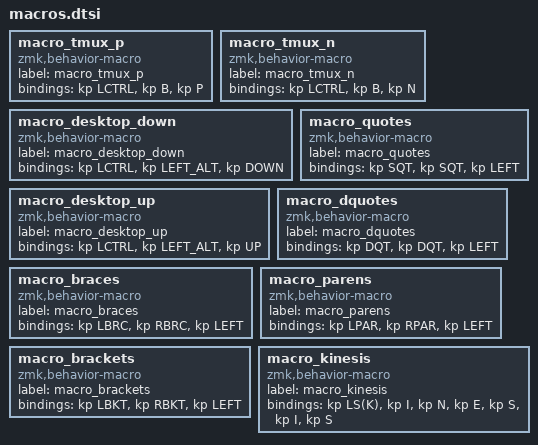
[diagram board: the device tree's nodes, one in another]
macro_tmux_p: macro_tmux_p{
compatible = "zmk,behavior-macro";
label = "macro_tmux_p";
#binding-cells = <0>;
bindings = <&kp LCTRL>, <&kp B>, <&kp P>;
};
macro_tmux_n: macro_tmux_n{
compatible = "zmk,behavior-macro";
label = "macro_tmux_n";
#binding-cells = <0>;
bindings = <&kp LCTRL>, <&kp B>, <&kp N>;
};
macro_desktop_down: macro_desktop_down{
compatible = "zmk,behavior-macro";
label = "macro_desktop_down";
#binding-cells = <0>;
bindings = <&kp LCTRL>, <&kp LEFT_ALT>, <&kp DOWN>;
};
macro_desktop_up: macro_desktop_up{
compatible = "zmk,behavior-macro";
label = "macro_desktop_up";
#binding-cells = <0>;
bindings = <&kp LCTRL>, <&kp LEFT_ALT>, <&kp UP>;
};
macro_quotes: macro_quotes{
compatible = "zmk,behavior-macro";
label = "macro_quotes";
#binding-cells = <0>;
bindings = <&kp SQT>, <&kp SQT>, <&kp LEFT>;
};
macro_dquotes: macro_dquotes{
compatible = "zmk,behavior-macro";
label = "macro_dquotes";
#binding-cells = <0>;
bindings = <&kp DQT>, <&kp DQT>, <&kp LEFT>;
};
macro_braces: macro_braces{
compatible = "zmk,behavior-macro";
label = "macro_braces";
#binding-cells = <0>;
bindings = <&kp LBRC>, <&kp RBRC>, <&kp LEFT>;
};
macro_parens: macro_parens{
compatible = "zmk,behavior-macro";
label = "macro_parens";
#binding-cells = <0>;
bindings = <&kp LPAR>, <&kp RPAR>, <&kp LEFT>;
};
macro_brackets: macro_brackets{
compatible = "zmk,behavior-macro";
label = "macro_brackets";
#binding-cells = <0>;
bindings = <&kp LBKT>, <&kp RBKT>, <&kp LEFT>;
};
macro_kinesis: macro_kinesis{
compatible = "zmk,behavior-macro";
label = "macro_kinesis";
#binding-cells = <0>;
bindings = <&kp LS(K)>, <&kp I>, <&kp N>, <&kp E>, <&kp S>, <&kp I>, <&kp S>;
};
